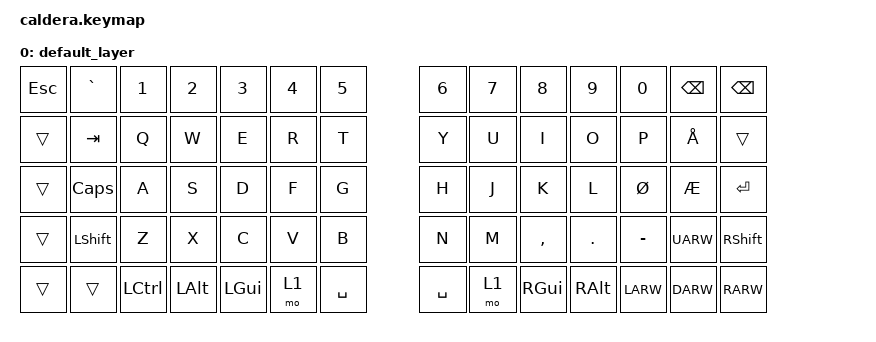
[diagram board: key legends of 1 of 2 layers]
#include <behaviors.dtsi>
#include <dt-bindings/zmk/keys.h>
#include <dt-bindings/zmk/bt.h>

/ {
        keymap {
                compatible = "zmk,keymap";

                default_layer {
// ---------------------------------------------------------------------------------
// | x |   `  |  1  |  2  |  3  |  4  |  5  |     |  6  |  7  |  8  |  9  |  0  | BKSP | x |
// | x |  TAB |  Q  |  W  |  E  |  R  |  T  |     |  Y  |  U  |  I  |  O  |  P  |  \   | x |
// | x | CAPS |  A  |  S  |  D  |  F  |  G  |     |  H  |  J  |  K  |  L  |  ;  |  ENT | x |
// | x | SHFT |  Z  |  X  |  C  |  V  |  B  |     |  N  |  M  |  ,  |  .  |  /  | APOS | x |
// | x | CTRL | ALT | GUI | SPC | SPC | SPC |     | SPC | LOW |LARW |DARW |UARW | RARW | x |

// ---------------------------------------------------------------------------------
// | ESC |   `  |  1  |  2  |  3  |  4  |  5  |     |  6  |  7  |  8  |  9  |  0  | BKSP | BKSP |
// | x   |  TAB |  Q  |  W  |  E  |  R  |  T  |     |  Y  |  U  |  I  |  O  |  P  |  Å   | ENT  |
// | x   | CAPS |  A  |  S  |  D  |  F  |  G  |     |  H  |  J  |  K  |  L  |  Ø  |  Æ   | ENT  |
// | x   | SHFT |  Z  |  X  |  C  |  V  |  B  |     |  N  |  M  |  ,  |  .  |  -  |  UP  | SHIFT|
// | x   | x    | CTR | OPT | CMD | LOW | SPC |     | SPC | LOW | CMD | OPT |LEFT | DOWN | RIGHT|
                        bindings = <
   &kp ESC  &kp GRAVE  &kp N1     &kp N2    &kp N3     &kp N4     &kp N5               &kp N6     &kp N7  &kp N8     &kp N9    &kp N0    &kp BSPC  &kp BSPC
   &trans   &kp TAB    &kp Q      &kp W     &kp E      &kp R      &kp T                &kp Y      &kp U   &kp I      &kp O     &kp P     &kp Å     &trans
   &trans   &kp CAPS   &kp A      &kp S     &kp D      &kp F      &kp G                &kp H      &kp J   &kp K      &kp L     &kp Ø     &kp Æ     &kp RET
   &trans   &kp LSHFT  &kp Z      &kp X     &kp C      &kp V      &kp B                &kp N      &kp M   &kp COMMA  &kp DOT   &kp MINUS &kp UARW  &kp RSHFT
   &trans   &trans     &kp LCTRL  &kp LALT  &kp LGUI   &mo 1      &kp SPACE            &kp SPACE  &mo 1   &kp RGUI   &kp RALT  &kp LARW  &kp DARW  &kp RARW
                        >;
                };
                lower_layer {
// ------------------------------------------------------------------------------------------------------------
// |       |  BT1  |  BT2  |  BT3  |  BT4  |  BT5  |          |       |       |       |       |       | BTCLR |
// |       |       |       |       |       |       |          |       |  {    |   }   |       |       |       |
// |       |       |       | LPAR  | RPAR  |       |          |       | LBKT  | RBKT  |       |       |       |
// |       |       |       |       |       |       |          |       |       |       |       |       |       |
                        bindings = <
   &trans    &trans    &bt BT_SEL 0   &bt BT_SEL 1   &bt BT_SEL 2   &bt BT_SEL 3   &bt BT_SEL 4           &trans    &trans    &trans    &trans      &trans  &bt BT_CLR  &trans
   &trans    &trans    &trans         &trans         &trans         &trans         &trans                 &trans    &kp LBRC  &kp RBRC  &trans      &trans  &trans      &trans
   &trans    &trans    &trans         &trans         &kp LPAR       &kp RPAR       &trans                 &trans    &kp LBKT  &kp RBKT  &kp MINUS   &kp EQUAL  &trans   &trans
   &trans    &trans    &trans         &trans         &trans         &trans         &trans                 &trans    &trans    &trans    &trans      &trans  &trans      &trans
                        >;
                };
        };
};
